# CH32F103xx register map
Vendor: WCH Ltd.; File version: 1.0
Registers are 32-bit, read-write, reset 0x0 unless marked. A register's access mark holds for its fields unless they carry their own. Offsets are from the block's base; [hi:lo] are bit positions; {n}, {i} and the like mark numbered series.

## CAN — Controller area network
Base 0x40006400
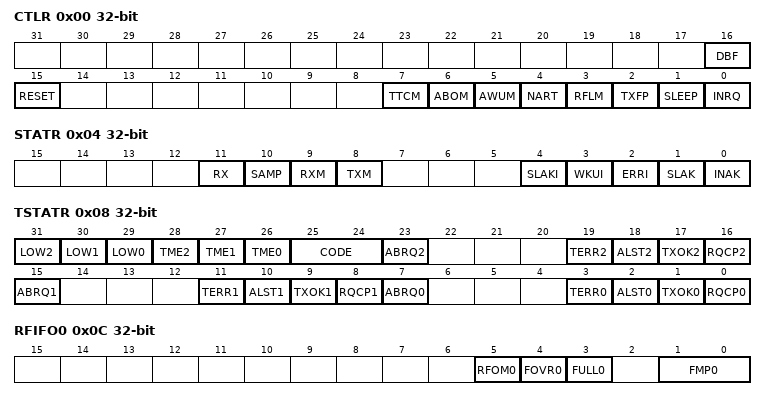
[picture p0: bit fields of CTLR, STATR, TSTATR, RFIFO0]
0x00 CTLR
  [16] DBF, [15] RESET, [7] TTCM, [6] ABOM, [5] AWUM, [4] NART, [3] RFLM, [2] TXFP, [1] SLEEP, [0] INRQ
0x04 STATR access per field
  [11] RX ro, [10] SAMP ro, [9] RXM ro, [8] TXM ro, [4] SLAKI rw, [3] WKUI rw, [2] ERRI rw, [1] SLAK ro, [0] INAK ro
0x08 TSTATR access per field
  [31] LOW2 ro — Lowest priority flag for mailbox 2
  [30] LOW1 ro — Lowest priority flag for mailbox 1
  [29] LOW0 ro — Lowest priority flag for mailbox 0
  [28] TME2 ro — Lowest priority flag for mailbox 2
  [27] TME1 ro — Lowest priority flag for mailbox 1
  [26] TME0 ro — Lowest priority flag for mailbox 0
  [25:24] CODE ro
  [23] ABRQ2 rw
  [19] TERR2 rw
  [18] ALST2 rw
  [17] TXOK2 rw
  [16] RQCP2 rw
  [15] ABRQ1 rw
  [11] TERR1 rw
  [10] ALST1 rw
  [9] TXOK1 rw
  [8] RQCP1 rw
  [7] ABRQ0 rw
  [3] TERR0 rw
  [2] ALST0 rw
  [1] TXOK0 rw
  [0] RQCP0 rw
0x0C RFIFO0 access per field
  [5] RFOM0 rw, [4] FOVR0 rw, [3] FULL0 rw, [1:0] FMP0 ro
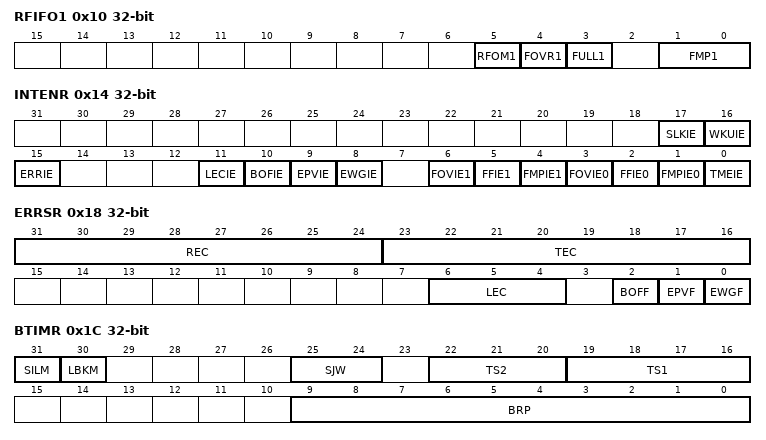
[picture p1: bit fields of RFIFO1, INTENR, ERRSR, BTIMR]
0x10 RFIFO1 access per field
  [5] RFOM1 rw, [4] FOVR1 rw, [3] FULL1 rw, [1:0] FMP1 ro
0x14 INTENR
  [17] SLKIE, [16] WKUIE, [15] ERRIE, [11] LECIE, [10] BOFIE, [9] EPVIE, [8] EWGIE, [6] FOVIE1, [5] FFIE1, [4] FMPIE1, [3] FOVIE0, [2] FFIE0, [1] FMPIE0, [0] TMEIE
0x18 ERRSR access per field
  [31:24] REC ro, [23:16] TEC ro, [6:4] LEC rw, [2] BOFF ro, [1] EPVF ro, [0] EWGF ro
0x1C BTIMR
  [31] SILM, [30] LBKM, [25:24] SJW, [22:20] TS2, [19:16] TS1, [9:0] BRP
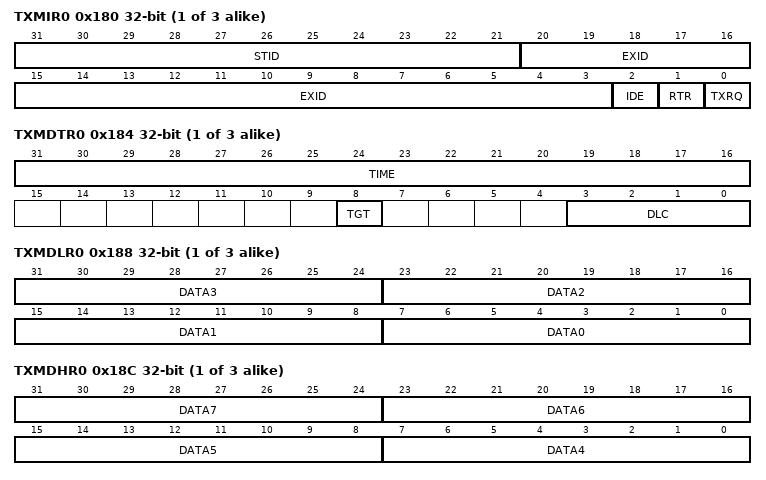
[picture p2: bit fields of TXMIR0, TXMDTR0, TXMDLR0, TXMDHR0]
{0x180+0x10*i} TXMIR{i} (i=0..2)
  [31:21] STID, [20:3] EXID, [2] IDE, [1] RTR, [0] TXRQ
{0x184+0x10*i} TXMDTR{i} (i=0..2)
  [31:16] TIME, [8] TGT, [3:0] DLC
{0x188+0x10*i} TXMDLR{i} (i=0..2)
  [8n+7:8n] DATA{n} (n=0..3)
{0x18C+0x10*i} TXMDHR{i} (i=0..2)
  [8n-25:8n-32] DATA{n} (n=4..7)
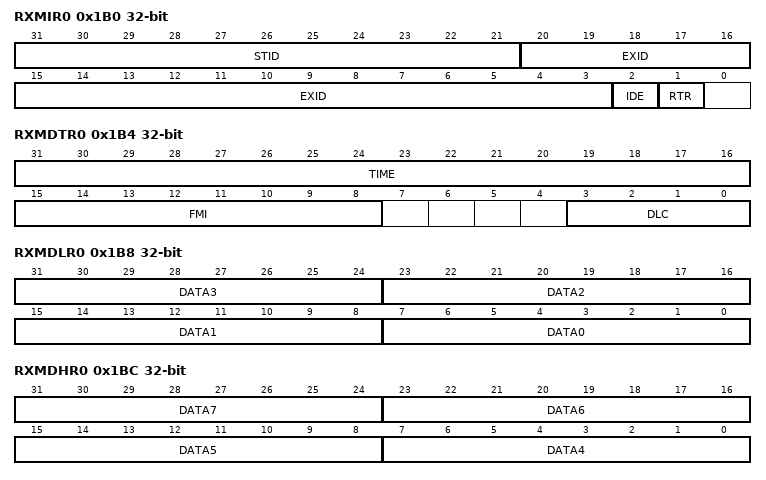
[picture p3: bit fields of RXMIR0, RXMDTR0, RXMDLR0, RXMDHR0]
0x1B0 RXMIR0 ro
  [31:21] STID, [20:3] EXID, [2] IDE, [1] RTR
0x1B4 RXMDTR0 ro
  [31:16] TIME, [15:8] FMI, [3:0] DLC
0x1B8 RXMDLR0 ro
  [8n+7:8n] DATA{n} (n=0..3)
0x1BC RXMDHR0 ro
  [8n-25:8n-32] DATA{n} (n=4..7)
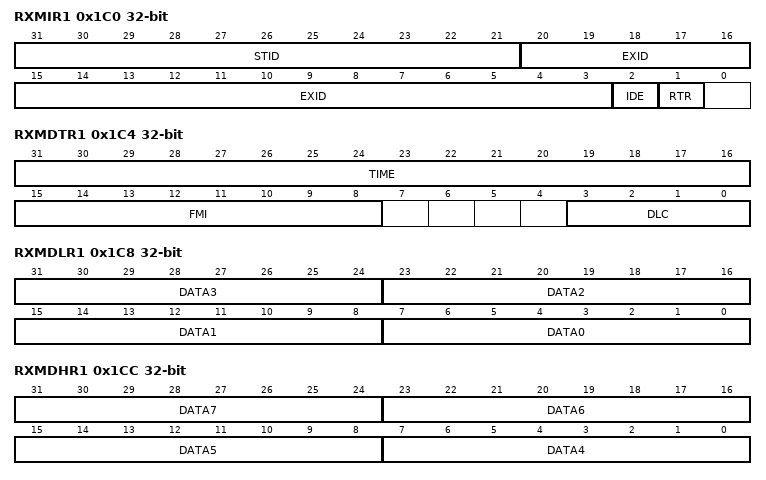
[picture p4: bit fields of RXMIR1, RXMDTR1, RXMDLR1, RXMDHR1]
0x1C0 RXMIR1 ro
  [31:21] STID, [20:3] EXID, [2] IDE, [1] RTR
0x1C4 RXMDTR1 ro
  [31:16] TIME, [15:8] FMI, [3:0] DLC
0x1C8 RXMDLR1 ro
  [8n+7:8n] DATA{n} (n=0..3)
0x1CC RXMDHR1 ro
  [8n-25:8n-32] DATA{n} (n=4..7)
0x200 FCTLR
  [0] FINIT
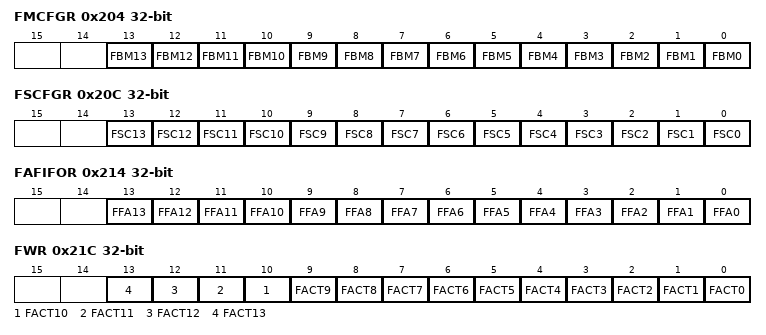
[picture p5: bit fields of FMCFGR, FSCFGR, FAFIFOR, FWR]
0x204 FMCFGR
  [n] FBM{n} (n=0..13) — Filter mode
0x20C FSCFGR
  [n] FSC{n} (n=0..13) — Filter scale configuration
0x214 FAFIFOR
  [n] FFA{n} (n=0..13) — Filter FIFO assignment for filter {n}
0x21C FWR
  [n] FACT{n} (n=0..13) — Filter active
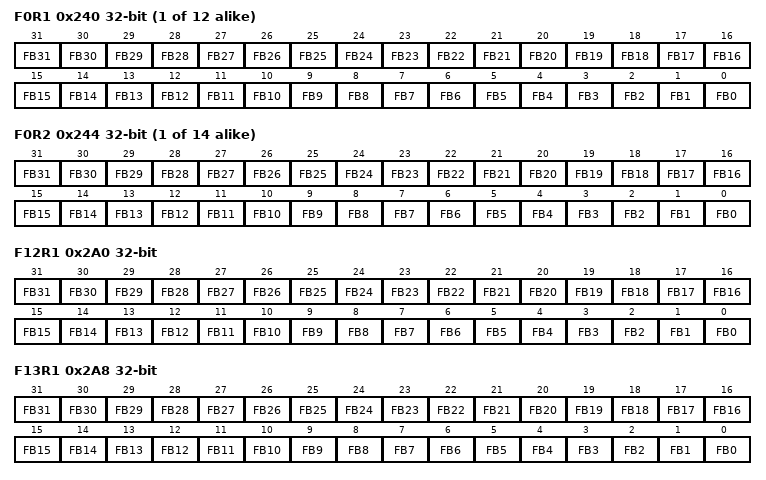
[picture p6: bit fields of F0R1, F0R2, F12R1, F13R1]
{0x240+8i} F{i}R1 (i=0..11) — Filter bank {i} register 1
  [n] FB{n} (n=0..31) — Filter bits
{0x244+8i} F{i}R2 (i=0..13) — Filter bank {i} register 2
  [n] FB{n} (n=0..31) — Filter bits
0x2A0 F12R1 — Filter bank 4 register 1
  [n] FB{n} (n=0..31) — Filter bits
0x2A8 F13R1 — Filter bank 13 register 1
  [n] FB{n} (n=0..31) — Filter bits

## DAC1 — Digital to analog converter
Base 0x40007400
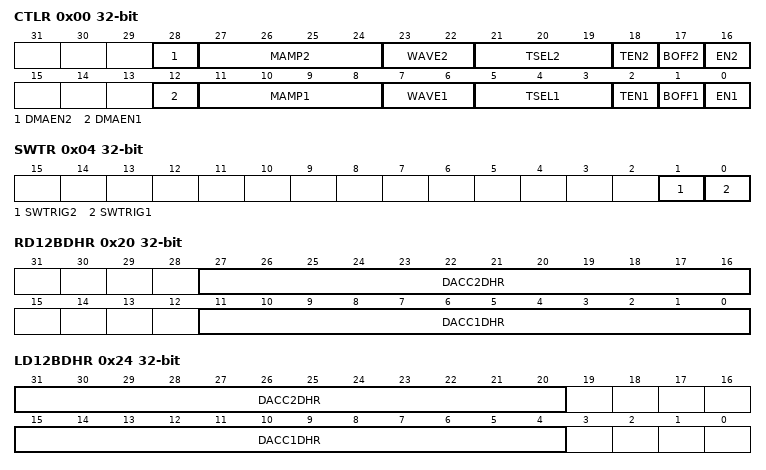
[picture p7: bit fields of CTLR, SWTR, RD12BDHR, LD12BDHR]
0x00 CTLR — Control register (DAC_CTLR)
  [28] DMAEN2 — DAC channel2 DMA enable
  [27:24] MAMP2 — DAC channel2 mask/amplitude selector
  [23:22] WAVE2 — DAC channel2 noise/triangle wave generation enable
  [21:19] TSEL2 — DAC channel2 trigger selection
  [18] TEN2 — DAC channel2 trigger enable
  [17] BOFF2 — DAC channel2 output buffer disable
  [16] EN2 — DAC channel2 enable
  [12] DMAEN1 — DAC channel1 DMA enable
  [11:8] MAMP1 — DAC channel1 mask/amplitude selector
  [7:6] WAVE1 — DAC channel1 noise/triangle wave generation enable
  [5:3] TSEL1 — DAC channel1 trigger selection
  [2] TEN1 — DAC channel1 trigger enable
  [1] BOFF1 — DAC channel1 output buffer disable
  [0] EN1 — DAC channel1 enable
0x04 SWTR wo — DAC software trigger register (DAC_SWTR)
  [1] SWTRIG2 — DAC channel2 software trigger
  [0] SWTRIG1 — DAC channel1 software trigger
0x08 R12BDHR1 — DAC channel1 12-bit right-aligned data holding register(DAC_R12BDHR1)
  [11:0] DACC1DHR — DAC channel1 12-bit right-aligned data
0x0C L12BDHR1 — DAC channel1 12-bit left aligned data holding register (DAC_L12BDHR1)
  [15:4] DACC1DHR — DAC channel1 12-bit left-aligned data
0x10 R8BDHR1 — DAC channel1 8-bit right aligned data holding register (DAC_R8BDHR1)
  [7:0] DACC1DHR — DAC channel1 8-bit right-aligned data
0x14 R12BDHR2 — DAC channel2 12-bit right aligned data holding register (DAC_R12BDHR2)
  [11:0] DACC2DHR — DAC channel2 12-bit right-aligned data
0x18 L12BDHR2 — DAC channel2 12-bit left aligned data holding register (DAC_L12BDHR2)
  [15:4] DACC2DHR — DAC channel2 12-bit left-aligned data
0x1C R8BDHR2 — DAC channel2 8-bit right-aligned data holding register (DAC_R8BDHR2)
  [7:0] DACC2DHR — DAC channel2 8-bit right-aligned data
0x20 RD12BDHR — Dual DAC 12-bit right-aligned data holding register (DAC_RD12BDHR), Bits 31:28 Reserved, Bits 15:12 Reserved
  [27:16] DACC2DHR — DAC channel2 12-bit right-aligned data
  [11:0] DACC1DHR — DAC channel1 12-bit right-aligned data
0x24 LD12BDHR — DUAL DAC 12-bit left aligned data holding register (DAC_LD12BDHR), Bits 19:16 Reserved, Bits 3:0 Reserved
  [31:20] DACC2DHR — DAC channel2 12-bit right-aligned data
  [15:4] DACC1DHR — DAC channel1 12-bit left-aligned data
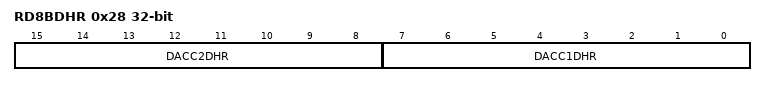
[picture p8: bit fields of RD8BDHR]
0x28 RD8BDHR — DUAL DAC 8-bit right aligned data holding register (DAC_RD8BDHR), Bits 31:16 Reserved
  [15:8] DACC2DHR — DAC channel2 8-bit right-aligned data
  [7:0] DACC1DHR — DAC channel1 8-bit right-aligned data
0x2C DOR1 ro — DAC channel1 data output register (DAC_DOR1)
  [11:0] DACC1DOR — DAC channel1 data output
0x30 DOR2 ro — DAC channel2 data output register (DAC_DOR2)
  [11:0] DACC2DOR — DAC channel2 data output
